# STM32H723 register map
File version: 2.2
CPU: CM7 r0p1, little endian, MPU, FPU, 4 interrupt priority bits
Registers are 32-bit, read-write, reset 0x0 unless marked. A register's access mark holds for its fields unless they carry their own. Offsets are from the block's base; [hi:lo] are bit positions; lines under a group give offsets from that group; {n}, {i} and the like mark numbered series.

## ADC1 (part 1 of 2) — Analog to Digital Converter
Base 0x40022000
Same registers: ADC2 0x40022100
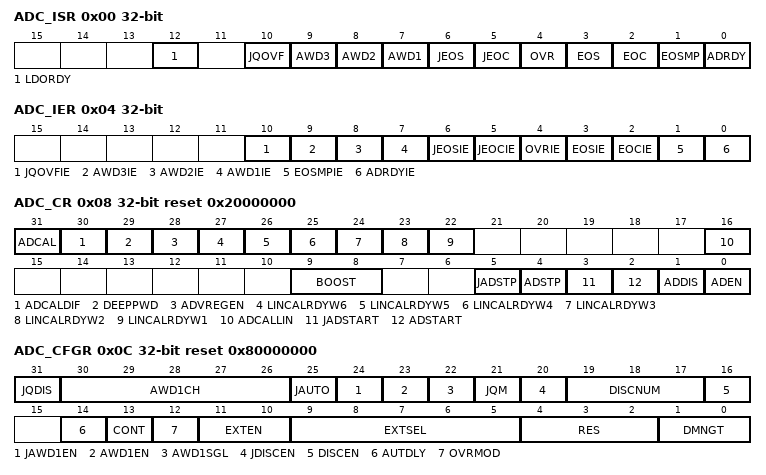
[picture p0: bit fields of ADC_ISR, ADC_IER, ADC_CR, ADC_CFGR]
0x00 ADC_ISR access per field — ADC interrupt and status register
  [12] LDORDY ro — ADC LDO output voltage ready bit This bit is set and cleared by hardware. It indicates that the ADC internal LDO output is ready and that the ADC can be enabled or calibrated. Note: Refer to for the availability of the LDO regulator.
    0=ADC LDO voltage regulator disabled; 1=ADC LDO voltage regulator enabled
  [10] JQOVF rw — Injected context queue overflow This bit is set by hardware when an Overflow of the Injected Queue of Context occurs. It is cleared by software writing 1 to it. Refer to for more information.
    0=No injected context queue overflow occurred (or the flag event was already acknowledged and cleared by software); 1=Injected context queue overflow has occurred
  [9] AWD3 rw — Analog watchdog 3 flag This bit is set by hardware when the converted voltage crosses the values programmed in the fields LT3[7:0] and HT3[7:0] of ADC_TR3 register. It is cleared by software writing 1 to it.
    0=No analog watchdog 3 event occurred (or the flag event was already acknowledged and cleared by software); 1=Analog watchdog 3 event occurred
  [8] AWD2 rw — Analog watchdog 2 flag This bit is set by hardware when the converted voltage crosses the values programmed in the fields LT2[7:0] and HT2[7:0] of ADC_TR2 register. It is cleared by software writing 1 to it.
    0=No analog watchdog 2 event occurred (or the flag event was already acknowledged and cleared by software); 1=Analog watchdog 2 event occurred
  [7] AWD1 rw — Analog watchdog 1 flag This bit is set by hardware when the converted voltage crosses the values programmed in the fields LT1[11:0] and HT1[11:0] of ADC_TR1 register. It is cleared by software. writing 1 to it.
    0=No analog watchdog 1 event occurred (or the flag event was already acknowledged and cleared by software); 1=Analog watchdog 1 event occurred
  [6] JEOS rw — Injected channel end of sequence flag This bit is set by hardware at the end of the conversions of all injected channels in the group. It is cleared by software writing 1 to it.
    0=Injected conversion sequence not complete (or the flag event was already acknowledged and cleared by software); 1=Injected conversions complete
  [5] JEOC rw — Injected channel end of conversion flag This bit is set by hardware at the end of each injected conversion of a channel when a new data is available in the corresponding ADC_JDRy register. It is cleared by software writing 1 to it or by reading the corresponding ADC_JDRy register
    0=Injected channel conversion not complete (or the flag event was already acknowledged and cleared by software); 1=Injected channel conversion complete
  [4] OVR rw — ADC overrun This bit is set by hardware when an overrun occurs on a regular channel, meaning that a new conversion has completed while the EOC flag was already set. It is cleared by software writing 1 to it.
    0=No overrun occurred (or the flag event was already acknowledged and cleared by software); 1=Overrun has occurred
  [3] EOS rw — End of regular sequence flag This bit is set by hardware at the end of the conversions of a regular sequence of channels. It is cleared by software writing 1 to it.
    0=Regular Conversions sequence not complete (or the flag event was already acknowledged and cleared by software); 1=Regular Conversions sequence complete
  [2] EOC rw — End of conversion flag This bit is set by hardware at the end of each regular conversion of a channel when a new data is available in the ADC_DR register. It is cleared by software writing 1 to it or by reading the ADC_DR register
    0=Regular channel conversion not complete (or the flag event was already acknowledged and cleared by software); 1=Regular channel conversion complete
  [1] EOSMP rw — End of sampling flag This bit is set by hardware during the conversion of any channel (only for regular channels), at the end of the sampling phase.
    0=not at the end of the sampling phase (or the flag event was already acknowledged and cleared by software); 1=End of sampling phase reached
  [0] ADRDY rw — ADC ready This bit is set by hardware after the ADC has been enabled (bit ADEN=1) and when the ADC reaches a state where it is ready to accept conversion requests. It is cleared by software writing 1 to it.
    0=ADC not yet ready to start conversion (or the flag event was already acknowledged and cleared by software); 1=ADC is ready to start conversion
0x04 ADC_IER — ADC interrupt enable register
  [10] JQOVFIE — Injected context queue overflow interrupt enable This bit is set and cleared by software to enable/disable the Injected Context Queue Overflow interrupt. Note: The software is allowed to write this bit only when JADSTART=0 (which ensures that no injected conversion is ongoing).
    0=Injected Context Queue Overflow interrupt disabled; 1=Injected Context Queue Overflow interrupt enabled. An interrupt is generated when the JQOVF bit is set.
  [9] AWD3IE — Analog watchdog 3 interrupt enable This bit is set and cleared by software to enable/disable the analog watchdog 2 interrupt. Note: The software is allowed to write this bit only when ADSTART=0 and JADSTART=0 (which ensures that no conversion is ongoing).
    0=Analog watchdog 3 interrupt disabled; 1=Analog watchdog 3 interrupt enabled
  [8] AWD2IE — Analog watchdog 2 interrupt enable This bit is set and cleared by software to enable/disable the analog watchdog 2 interrupt. Note: The software is allowed to write this bit only when ADSTART=0 and JADSTART=0 (which ensures that no conversion is ongoing).
    0=Analog watchdog 2 interrupt disabled; 1=Analog watchdog 2 interrupt enabled
  [7] AWD1IE — Analog watchdog 1 interrupt enable This bit is set and cleared by software to enable/disable the analog watchdog 1 interrupt. Note: The software is allowed to write this bit only when ADSTART=0 and JADSTART=0 (which ensures that no conversion is ongoing).
    0=Analog watchdog 1 interrupt disabled; 1=Analog watchdog 1 interrupt enabled
  [6] JEOSIE — End of injected sequence of conversions interrupt enable This bit is set and cleared by software to enable/disable the end of injected sequence of conversions interrupt. Note: The software is allowed to write this bit only when JADSTART=0 (which ensures that no injected conversion is ongoing).
    0=JEOS interrupt disabled; 1=JEOS interrupt enabled. An interrupt is generated when the JEOS bit is set.
  [5] JEOCIE — End of injected conversion interrupt enable This bit is set and cleared by software to enable/disable the end of an injected conversion interrupt. Note: The software is allowed to write this bit only when JADSTART is cleared to 0 (no injected conversion is ongoing).
    0=JEOC interrupt disabled; 1=JEOC interrupt enabled. An interrupt is generated when the JEOC bit is set.
  [4] OVRIE — Overrun interrupt enable This bit is set and cleared by software to enable/disable the Overrun interrupt of a regular conversion. Note: The software is allowed to write this bit only when ADSTART=0 (which ensures that no regular conversion is ongoing).
    0=Overrun interrupt disabled; 1=Overrun interrupt enabled. An interrupt is generated when the OVR bit is set.
  [3] EOSIE — End of regular sequence of conversions interrupt enable This bit is set and cleared by software to enable/disable the end of regular sequence of conversions interrupt. Note: The software is allowed to write this bit only when ADSTART=0 (which ensures that no regular conversion is ongoing).
    0=EOS interrupt disabled; 1=EOS interrupt enabled. An interrupt is generated when the EOS bit is set.
  [2] EOCIE — End of regular conversion interrupt enable This bit is set and cleared by software to enable/disable the end of a regular conversion interrupt. Note: The software is allowed to write this bit only when ADSTART=0 (which ensures that no regular conversion is ongoing).
    0=EOC interrupt disabled; 1=EOC interrupt enabled. An interrupt is generated when the EOC bit is set.
  [1] EOSMPIE — End of sampling flag interrupt enable for regular conversions This bit is set and cleared by software to enable/disable the end of the sampling phase interrupt for regular conversions. Note: The software is allowed to write this bit only when ADSTART=0 (which ensures that no regular conversion is ongoing).
    0=EOSMP interrupt disabled; 1=EOSMP interrupt enabled. An interrupt is generated when the EOSMP bit is set.
  [0] ADRDYIE — ADC ready interrupt enable This bit is set and cleared by software to enable/disable the ADC Ready interrupt. Note: The software is allowed to write this bit only when ADSTART=0 and JADSTART=0 (which ensures that no conversion is ongoing).
    0=ADRDY interrupt disabled; 1=ADRDY interrupt enabled. An interrupt is generated when the ADRDY bit is set.
0x08 ADC_CR reset 0x20000000 — ADC control register
  [31] ADCAL — ADC calibration This bit is set by software to start the calibration of the ADC. Program first the bit ADCALDIF to determine if this calibration applies for single-ended or differential inputs mode. It is cleared by hardware after calibration is complete. Note: The software is allowed to launch a calibration by setting ADCAL only when ADEN=0. The software is allowed to update the calibration factor by writing ADC_CALFACT only when ADEN=1 and ADSTART=0 and JADSTART=0 (ADC enabled and no conversion is ongoing)
    0=Calibration complete; 1=Write 1 to calibrate the ADC. Read at 1 means that a calibration in progress.
  [30] ADCALDIF — Differential mode for calibration This bit is set and cleared by software to configure the single-ended or differential inputs mode for the calibration. Note: The software is allowed to write this bit only when the ADC is disabled and is not calibrating (ADCAL=0, JADSTART=0, JADSTP=0, ADSTART=0, ADSTP=0, ADDIS=0 and ADEN=0).
    0=Writing ADCAL will launch a calibration in Single-ended inputs Mode; 1=Writing ADCAL will launch a calibration in Differential inputs Mode
  [29] DEEPPWD — Deep-power-down enable This bit is set and cleared by software to put the ADC in deep-power-down mode. Note: The software is allowed to write this bit only when the ADC is disabled (ADCAL=0, JADSTART=0, JADSTP=0, ADSTART=0, ADSTP=0, ADDIS=0 and ADEN=0).
    0=ADC not in deep-power down; 1=ADC in deep-power-down (default reset state)
  [28] ADVREGEN — ADC voltage regulator enable This bits is set by software to enable the ADC voltage regulator. Before performing any operation such as launching a calibration or enabling the ADC, the ADC voltage regulator must first be enabled and the software must wait for the regulator start-up time. For more details about the ADC voltage regulator enable and disable sequences, refer to (ADVREGEN). The software can program this bitfield only when the ADC is disabled (ADCAL=0, JADSTART=0, ADSTART=0, ADSTP=0, ADDIS=0 and ADEN=0).
    0=ADC Voltage regulator disabled; 1=ADC Voltage regulator enabled
  [27] LINCALRDYW6 — Linearity calibration ready Word 6 This control / status bit allows to read/write the 6th linearity calibration factor. When the linearity calibration is complete, this bit is set. A bit clear will launch the transfer of the linearity factor 6 into the LINCALFACT[29:0] of the ADC_CALFACT2 register. The bit will be reset by hardware when the ADC_CALFACT2 register can be read (software must poll the bit until it is cleared). When the LINCALRDYW6 bit is reset, a new linearity factor 6 value can be written into the LINCALFACT[29:0] of the ADC_CALFACT2 register. A bit set will launch the linearity factor 6 update and the bit will be effectively set by hardware once the update will be done (software must poll the bit until it is set to indicate the write is effective). Note: ADC_CALFACT2[29:10] contains 0. ADC_CALFACT2[9:0] corresponds linearity correction factor bits[159:150]. The software is allowed to toggle this bit only if the LINCALRDYW5, LINCALRDYW4, LINCALRDYW3, LINCALRDYW2 and LINCALRDYW1 bits are left unchanged, see chapter for details. The software is allowed to update the linearity calibration factor by writing LINCALRDYWx only when ADEN=1 and ADSTART=0 and JADSTART=0 (ADC enabled and no conversion is ongoing)
  [26] LINCALRDYW5 — Linearity calibration ready Word 5 Refer to LINCALRDYW6 description. Note: ADC_CALFACT2[29:0] corresponds linearity correction factor bits[149:120]. The software is allowed to toggle this bit only if the LINCALRDYW6, LINCALRDYW5, LINCALRDYW3, LINCALRDYW2 and LINCALRDYW1 bits are left unchanged.
  [25] LINCALRDYW4 — Linearity calibration ready Word 4 Refer to LINCALRDYW6 description. Note: ADC_CALFACT2[29:0] correspond linearity correction factor bits[119:90]. The software is allowed to toggle this bit only if the LINCALRDYW6, LINCALRDYW5, LINCALRDYW3, LINCALRDYW2 and LINCALRDYW1 bits are left unchanged.
  [24] LINCALRDYW3 — Linearity calibration ready Word 3 Refer to LINCALRDYW6 description. Note: ADC_CALFACT2[29:0] corresponds linearity correction factor bits[89:60]. The software is allowed to toggle this bit only if the LINCALRDYW6, LINCALRDYW5, LINCALRDYW4, LINCALRDYW2 and LINCALRDYW1 bits are left unchanged.
  [23] LINCALRDYW2 — Linearity calibration ready Word 2 Refer to LINCALRDYW6 description. Note: ADC_CALFACT2[29:0] corresponds linearity correction factor bits[59:30]. The software is allowed to toggle this bit only if the LINCALRDYW6, LINCALRDYW5, LINCALRDYW4, LINCALRDYW3 and LINCALRDYW1 bits are left unchanged.
  [22] LINCALRDYW1 — Linearity calibration ready Word 1 Refer to LINCALRDYW6 description. Note: ADC_CALFACT2[29:0] corresponds linearity correction factor bits[29:0]. The software is allowed to toggle this bit only if the LINCALRDYW6, LINCALRDYW5, LINCALRDYW4, LINCALRDYW3 and LINCALRDYW2 bits are left unchanged.
  [16] ADCALLIN — Linearity calibration This bit is set and cleared by software to enable the Linearity calibration. Note: The software is allowed to write this bit only when the ADC is disabled and is not calibrating (ADCAL=0, JADSTART=0, JADSTP=0, ADSTART=0, ADSTP=0, ADDIS=0 and ADEN=0).
    0=Writing ADCAL will launch a calibration without the Linearity calibration; 1=Writing ADCAL will launch a calibration with he Linearity calibration
  [9:8] BOOST — Boost mode control This bitfield is set and cleared by software to enable/disable the Boost mode. Note: The software is allowed to write this bit only when ADSTART=0 and JADSTART=0 (which ensures that no conversion is ongoing). When dual mode is enabled (bits DAMDF of ADCx_CCR register are not equal to zero), the BOOST bitfield of the slave ADC is no more writable and its content must be equal to the master ADC BOOST bitfield.
    0=used when ADC clock less than or equal 6.25 MHz; 1=used when 6.25 MHz ADC clock frequency less than or equal 12.5 MHz; 2=used when 12.5 MHz ADC clock less than or equal 25.0 MHz; 3=used when 25.0 MHz ADC clock less than or equal 50.0 MHz
  [5] JADSTP — ADC stop of injected conversion command This bit is set by software to stop and discard an ongoing injected conversion (JADSTP Command). It is cleared by hardware when the conversion is effectively discarded and the ADC injected sequence and triggers can be re-configured. The ADC is then ready to accept a new start of injected conversions (JADSTART command). Note: The software is allowed to set JADSTP only when JADSTART=1 and ADDIS=0 (ADC is enabled and eventually converting an injected conversion and there is no pending request to disable the ADC). In auto-injection mode (JAUTO=1), setting ADSTP bit aborts both regular and injected conversions (do not use JADSTP)
    0=No ADC stop injected conversion command ongoing; 1=Write 1 to stop injected conversions ongoing. Read 1 means that an ADSTP command is in progress.
  [4] ADSTP — ADC stop of regular conversion command This bit is set by software to stop and discard an ongoing regular conversion (ADSTP Command). It is cleared by hardware when the conversion is effectively discarded and the ADC regular sequence and triggers can be re-configured. The ADC is then ready to accept a new start of regular conversions (ADSTART command). Note: The software is allowed to set ADSTP only when ADSTART=1 and ADDIS=0 (ADC is enabled and eventually converting a regular conversion and there is no pending request to disable the ADC). In auto-injection mode (JAUTO=1), setting ADSTP bit aborts both regular and injected conversions (do not use JADSTP). In dual ADC regular simultaneous mode and interleaved mode, the bit ADSTP of the master ADC must be used to stop regular conversions. The other ADSTP bit is inactive.
    0=No ADC stop regular conversion command ongoing; 1=Write 1 to stop regular conversions ongoing. Read 1 means that an ADSTP command is in progress.
  [3] JADSTART — ADC start of injected conversion This bit is set by software to start ADC conversion of injected channels. Depending on the configuration bits JEXTEN, a conversion will start immediately (software trigger configuration) or once an injected hardware trigger event occurs (hardware trigger configuration). It is cleared by hardware: in single conversion mode when software trigger is selected (JEXTSEL=0x0): at the assertion of the End of Injected Conversion Sequence (JEOS) flag. in all cases: after the execution of the JADSTP command, at the same time that JADSTP is cleared by hardware. Note: The software is allowed to set JADSTART only when ADEN=1 and ADDIS=0 (ADC is enabled and there is no pending request to disable the ADC). In auto-injection mode (JAUTO=1), regular and auto-injected conversions are started by setting bit ADSTART (JADSTART must be kept cleared)
    0=No ADC injected conversion is ongoing; 1=Write 1 to start injected conversions. Read 1 means that the ADC is operating and eventually converting an injected channel.
  [2] ADSTART — ADC start of regular conversion This bit is set by software to start ADC conversion of regular channels. Depending on the configuration bits EXTEN, a conversion will start immediately (software trigger configuration) or once a regular hardware trigger event occurs (hardware trigger configuration). It is cleared by hardware: in single conversion mode (CONT=0, DISCEN=0) when software trigger is selected (EXTEN=0x0): at the assertion of the End of Regular Conversion Sequence (EOS) flag. In discontinuous conversion mode (CONT=0, DISCEN=1), when the software trigger is selected (EXTEN=0x0): at the end of conversion (EOC) flag. in all other cases: after the execution of the ADSTP command, at the same time that ADSTP is cleared by hardware. Note: The software is allowed to set ADSTART only when ADEN=1 and ADDIS=0 (ADC is enabled and there is no pending request to disable the ADC) In auto-injection mode (JAUTO=1), regular and auto-injected conversions are started by setting bit ADSTART (JADSTART must be kept cleared)
    0=No ADC regular conversion is ongoing; 1=Write 1 to start regular conversions. Read 1 means that the ADC is operating and eventually converting a regular channel.
  [1] ADDIS — ADC disable command This bit is set by software to disable the ADC (ADDIS command) and put it into power-down state (OFF state). It is cleared by hardware once the ADC is effectively disabled (ADEN is also cleared by hardware at this time). Note: The software is allowed to set ADDIS only when ADEN=1 and both ADSTART=0 and JADSTART=0 (which ensures that no conversion is ongoing)
    0=no ADDIS command ongoing; 1=Write 1 to disable the ADC. Read 1 means that an ADDIS command is in progress.
  [0] ADEN — ADC enable control This bit is set by software to enable the ADC. The ADC will be effectively ready to operate once the flag ADRDY has been set. It is cleared by hardware when the ADC is disabled, after the execution of the ADDIS command. Note: The software is allowed to set ADEN only when all bits of ADC_CR registers are 0 (ADCAL=0, JADSTART=0, ADSTART=0, ADSTP=0, ADDIS=0 and ADEN=0) except for bit ADVREGEN which must be 1 (and the software must have wait for the startup time of the voltage regulator)
    0=ADC is disabled (OFF state); 1=Write 1 to enable the ADC
0x0C ADC_CFGR reset 0x80000000 — ADC configuration register
  [31] JQDIS — Injected Queue disable These bits are set and cleared by software to disable the Injected Queue mechanism: Note: The software is allowed to write this bit only when ADSTART=0 and JADSTART=0 (which ensures that no regular nor injected conversion is ongoing). A set or reset of JQDIS bit causes the injected queue to be flushed and the JSQR register is cleared.
    0=Injected Queue enabled; 1=Injected Queue disabled
  [30:26] AWD1CH — Analog watchdog 1 channel selection These bits are set and cleared by software. They select the input channel to be guarded by the analog watchdog. ..... others: Reserved, must not be used Note: The channel selected by AWD1CH must be also selected into the SQRi or JSQRi registers. The software is allowed to write these bits only when ADSTART=0 and JADSTART=0 (which ensures that no conversion is ongoing).
    0=ADC analog input channel-0 monitored by AWD1; 1=ADC analog input channel-1 monitored by AWD1; 18=ADC analog input channel-19 monitored by AWD1
  [25] JAUTO — Automatic injected group conversion This bit is set and cleared by software to enable/disable automatic injected group conversion after regular group conversion. Note: The software is allowed to write this bit only when ADSTART=0 and JADSTART=0 (which ensures that no regular nor injected conversion is ongoing). When dual mode is enabled (DAMDF bits in ADCx_CCR register are not equal to zero), the bit JAUTO of the slave ADC is no more writable and its content is equal to the bit JAUTO of the master ADC.
    0=Automatic injected group conversion disabled; 1=Automatic injected group conversion enabled
  [24] JAWD1EN — Analog watchdog 1 enable on injected channels This bit is set and cleared by software Note: The software is allowed to write this bit only when JADSTART=0 (which ensures that no injected conversion is ongoing).
    0=Analog watchdog 1 disabled on injected channels; 1=Analog watchdog 1 enabled on injected channels
  [23] AWD1EN — Analog watchdog 1 enable on regular channels This bit is set and cleared by software Note: The software is allowed to write this bit only when ADSTART=0 (which ensures that no regular conversion is ongoing).
    0=Analog watchdog 1 disabled on regular channels; 1=Analog watchdog 1 enabled on regular channels
  [22] AWD1SGL — Enable the watchdog 1 on a single channel or on all channels This bit is set and cleared by software to enable the analog watchdog on the channel identified by the AWD1CH[4:0] bits or on all the channels Note: The software is allowed to write this bit only when ADSTART=0 and JADSTART=0 (which ensures that no conversion is ongoing).
    0=Analog watchdog 1 enabled on all channels; 1=Analog watchdog 1 enabled on a single channel
  [21] JQM — JSQR queue mode This bit is set and cleared by software. It defines how an empty Queue is managed. Refer to for more information. Note: The software is allowed to write this bit only when JADSTART=0 (which ensures that no injected conversion is ongoing). When dual mode is enabled (DAMDF bits in ADCx_CCR register are not equal to zero), the bit JQM of the slave ADC is no more writable and its content is equal to the bit JQM of the master ADC.
    0=JSQR Mode 0: The Queue is never empty and maintains the last written configuration into JSQR; 1=JSQR Mode 1: The Queue can be empty and when this occurs, the software and hardware triggers of the injected sequence are both internally disabled just after the completion of the last valid injected sequence
  [20] JDISCEN — Discontinuous mode on injected channels This bit is set and cleared by software to enable/disable discontinuous mode on the injected channels of a group. Note: The software is allowed to write this bit only when JADSTART=0 (which ensures that no injected conversion is ongoing). It is not possible to use both auto-injected mode and discontinuous mode simultaneously: the bits DISCEN and JDISCEN must be kept cleared by software when JAUTO is set. When dual mode is enabled (bits DAMDF of ADCx_CCR register are not equal to zero), the bit JDISCEN of the slave ADC is no more writable and its content is equal to the bit JDISCEN of the master ADC.
    0=Discontinuous mode on injected channels disabled; 1=Discontinuous mode on injected channels enabled
  [19:17] DISCNUM — Discontinuous mode channel count These bits are written by software to define the number of regular channels to be converted in discontinuous mode, after receiving an external trigger. ... Note: The software is allowed to write these bits only when ADSTART=0 (which ensures that no regular conversion is ongoing). When dual mode is enabled (DAMDF bits in ADCx_CCR register are not equal to zero), the bits DISCNUM[2:0] of the slave ADC are no more writable and their content is equal to the bits DISCNUM[2:0] of the master ADC.
    0=1 channel; 1=2 channels; 7=8 channels
  [16] DISCEN — Discontinuous mode for regular channels This bit is set and cleared by software to enable/disable Discontinuous mode for regular channels. Note: It is not possible to have both discontinuous mode and continuous mode enabled: it is forbidden to set both DISCEN=1 and CONT=1. It is not possible to use both auto-injected mode and discontinuous mode simultaneously: the bits DISCEN and JDISCEN must be kept cleared by software when JAUTO is set. The software is allowed to write this bit only when ADSTART=0 (which ensures that no regular conversion is ongoing). When dual mode is enabled (DAMDF bits in ADCx_CCR register are not equal to zero), the bit DISCEN of the slave ADC is no more writable and its content is equal to the bit DISCEN of the master ADC.
    0=Discontinuous mode for regular channels disabled; 1=Discontinuous mode for regular channels enabled
  [14] AUTDLY — Delayed conversion mode This bit is set and cleared by software to enable/disable the Auto Delayed Conversion mode.. Note: The software is allowed to write this bit only when ADSTART=0 and JADSTART=0 (which ensures that no conversion is ongoing). When dual mode is enabled (DAMDF bits in ADCx_CCR register are not equal to zero), the bit AUTDLY of the slave ADC is no more writable and its content is equal to the bit AUTDLY of the master ADC.
    0=Auto-delayed conversion mode off; 1=Auto-delayed conversion mode on
  [13] CONT — Single / continuous conversion mode for regular conversions This bit is set and cleared by software. If it is set, regular conversion takes place continuously until it is cleared. Note: It is not possible to have both discontinuous mode and continuous mode enabled: it is forbidden to set both DISCEN=1 and CONT=1. The software is allowed to write this bit only when ADSTART=0 (which ensures that no regular conversion is ongoing). When dual mode is enabled (DAMDF bits in ADCx_CCR register are not equal to zero), the bit CONT of the slave ADC is no more writable and its content is equal to the bit CONT of the master ADC.
    0=Single conversion mode; 1=Continuous conversion mode
  [12] OVRMOD — Overrun Mode This bit is set and cleared by software and configure the way data overrun is managed. Note: The software is allowed to write this bit only when ADSTART=0 (which ensures that no regular conversion is ongoing).
    0=ADC_DR register is preserved with the old data when an overrun is detected; 1=ADC_DR register is overwritten with the last conversion result when an overrun is detected
  [11:10] EXTEN — External trigger enable and polarity selection for regular channels These bits are set and cleared by software to select the external trigger polarity and enable the trigger of a regular group. Note: The software is allowed to write these bits only when ADSTART=0 (which ensures that no regular conversion is ongoing).
    0=Hardware trigger detection disabled (conversions can be launched by software); 1=Hardware trigger detection on the rising edge; 2=Hardware trigger detection on the falling edge; 3=Hardware trigger detection on both the rising and falling edges
  [9:5] EXTSEL — External trigger selection for regular group These bits select the external event used to trigger the start of conversion of a regular group: ... Note: The software is allowed to write these bits only when ADSTART=0 (which ensures that no regular conversion is ongoing).
    {v}=Event {v} (v=0..7); 31=Event 31
  [4:2] RES — Data resolution These bits are written by software to select the resolution of the conversion. Others: Reserved, must not be used. Note: The software is allowed to write these bits only when ADSTART=0 and JADSTART=0 (which ensures that no conversion is ongoing).
    0=16 bits; 1=14 bits in legacy mode (not optimized power consumption); 2=12 bits in legacy mode (not optimized power consumption); 5=14 bits; 6=12 bits; 3=10 bits; 7=8 bits
  [1:0] DMNGT — Data Management configuration This bit is set and cleared by software to select how ADC interface output data are managed. Note: The software is allowed to write this bit only when ADSTART=0 and JADSTART=0 (which ensures that no conversion is ongoing). In dual-ADC modes, this bit is not relevant and replaced by control bit DAMDF of the ADCx_CCR register.
    0=Regular conversion data stored in DR only; 1=DMA One Shot Mode selected; 2=DFSDM mode selected; 3=DMA Circular Mode selected

## Notices in the file
Copyright (c) 2025 STMicroelectronics.
SPDX-License-Identifier: Apache-2.0
Licensed under the Apache License, Version 2.0 (the "License");
you may not use this file except in compliance with the License.
You may obtain a copy of the License at
http://www.apache.org/licenses/LICENSE-2.0
Unless required by applicable law or agreed to in writing, software
distributed under the License is distributed on an "AS IS" BASIS,
WITHOUT WARRANTIES OR CONDITIONS OF ANY KIND, either express or implied.
See the License for the specific language governing permissions and
limitations under the License.
